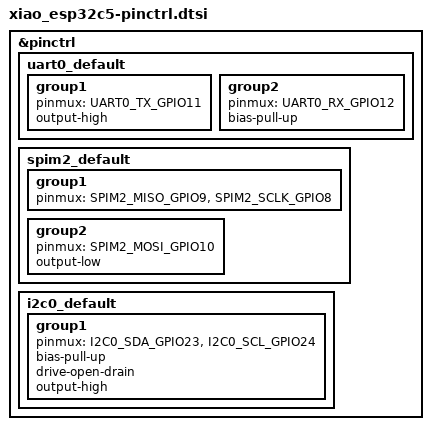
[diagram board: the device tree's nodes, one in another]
/*
 * SPDX-FileCopyrightText: Copyright The Zephyr Project Contributors
 * SPDX-License-Identifier: Apache-2.0
 */

/*
 * ---- ONE LINE ADDED TO UPSTREAM'S FILE ---------------------------------
 *
 * Upstream includes only esp32c5-pinctrl.h, because upstream's copy of that
 * header self-includes its two dependencies:
 *
 *     #include "esp-pinctrl-common.h"      <- defines ESP32_PINMUX()
 *     #include "esp32c5-gpio-sigmap.h"     <- defines ESP_U0TXD_OUT etc.
 *
 * **The copy in the tree this project pins does not.** There they are only
 * named in a doc comment, and every board is expected to include all three —
 * which is what zephyr/boards/espressif/esp32c5_devkitc's own pinctrl dtsi
 * does. So this file follows the in-tree convention rather than upstream's.
 *
 * The failure without them is loud but does not name the cause: the
 * preprocessor leaves `UART0_TX_GPIO11` unexpanded and the devicetree parser
 * reports "parse error: expected number or parenthesized expression" against
 * the first `pinmux` line.
 *
 * Harmless once the pinned tree catches up — the headers are all guarded — so
 * a future refresh from upstream should re-add these two lines rather than
 * take upstream's version wholesale.
 */
#include <zephyr/dt-bindings/pinctrl/esp-pinctrl-common.h>
#include <zephyr/dt-bindings/pinctrl/esp32c5-pinctrl.h>
#include <zephyr/dt-bindings/pinctrl/esp32c5-gpio-sigmap.h>

&pinctrl {
	uart0_default: uart0_default {
		group1 {
			pinmux = <UART0_TX_GPIO11>;
			output-high;
		};

		group2 {
			pinmux = <UART0_RX_GPIO12>;
			bias-pull-up;
		};
	};

	spim2_default: spim2_default {
		group1 {
			pinmux = <SPIM2_MISO_GPIO9>,
				 <SPIM2_SCLK_GPIO8>;
		};

		group2 {
			pinmux = <SPIM2_MOSI_GPIO10>;
			output-low;
		};
	};

	i2c0_default: i2c0_default {
		group1 {
			pinmux = <I2C0_SDA_GPIO23>,
				 <I2C0_SCL_GPIO24>;
			bias-pull-up;
			drive-open-drain;
			output-high;
		};
	};
};
